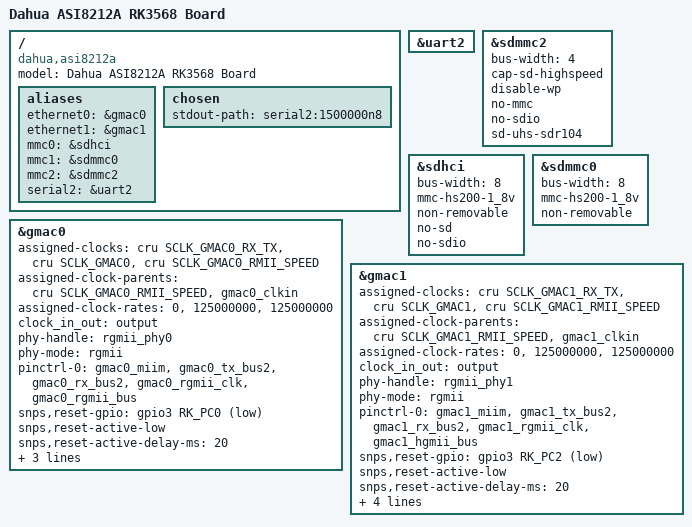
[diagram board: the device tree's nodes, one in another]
// SPDX-License-Identifier: (GPL-2.0+ OR MIT)

/dts-v1/;
#include <dt-bindings/gpio/gpio.h>
#include <dt-bindings/pinctrl/rockchip.h>
#include "rk3568.dtsi"

/ {
	model = "Dahua ASI8212A RK3568 Board";
	compatible = "dahua,asi8212a", "rockchip,rk3568";

	aliases {
		ethernet0 = &gmac0;
		ethernet1 = &gmac1;
		mmc0 = &sdhci;
		mmc1 = &sdmmc0;
		mmc2 = &sdmmc2;
		serial2 = &uart2;
	};

	chosen {
		stdout-path = "serial2:1500000n8";
	};
};

&uart2 {
	status = "okay";
};

&sdmmc2 {
	bus-width = <4>;
	cap-sd-highspeed;
	disable-wp;
	no-mmc;
	no-sdio;
	sd-uhs-sdr104;
	status = "okay";
};

&sdhci {
	bus-width = <8>;
	mmc-hs200-1_8v;
	non-removable;
	no-sd;
	no-sdio;
	status = "okay";
};

&sdmmc0 {
	bus-width = <8>;
	mmc-hs200-1_8v;
	non-removable;
	status = "okay";
};

&gmac0 {
	assigned-clocks = <&cru SCLK_GMAC0_RX_TX>, <&cru SCLK_GMAC0>, <&cru SCLK_GMAC0_RMII_SPEED>;
	assigned-clock-parents = <&cru SCLK_GMAC0_RMII_SPEED>, <&gmac0_clkin>;
	assigned-clock-rates = <0>, <125000000>, <125000000>;
	clock_in_out = "output";
	phy-handle = <&rgmii_phy0>;
	phy-mode = "rgmii";
	pinctrl-names = "default";
	pinctrl-0 = <&gmac0_miim &gmac0_tx_bus2 &gmac0_rx_bus2 &gmac0_rgmii_clk &gmac0_rgmii_bus>;
	snps,reset-gpio = <&gpio3 RK_PC0 GPIO_ACTIVE_LOW>;
	snps,reset-active-low;
	snps,reset-active-delay-ms = <20>;
	snps,reset-delays-us = <2>;
	tx_delay = <0x4f>;
	rx_delay = <0x2f>;
	status = "okay";
};

&gmac1 {
	assigned-clocks = <&cru SCLK_GMAC1_RX_TX>, <&cru SCLK_GMAC1>, <&cru SCLK_GMAC1_RMII_SPEED>;
	assigned-clock-parents = <&cru SCLK_GMAC1_RMII_SPEED>, <&gmac1_clkin>;
	assigned-clock-rates = <0>, <125000000>, <125000000>;
	clock_in_out = "output";
	phy-handle = <&rgmii_phy1>;
	phy-mode = "rgmii";
	pinctrl-names = "default";
	pinctrl-0 = <&gmac1_miim &gmac1_tx_bus2 &gmac1_rx_bus2 &gmac1_rgmii_clk &gmac1_hgmii_bus>;
	snps,reset-gpio = <&gpio3 RK_PC2 GPIO_ACTIVE_LOW>;
	snps,reset-active-low;
	snps,reset-active-delay-ms = <20>;
	snps,reset-delays-us = <15>;
	snps,reset-ms = <15>;
	tx_delay = <0x4f>;
	rx_delay = <0x2d>;
	status = "okay";
};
